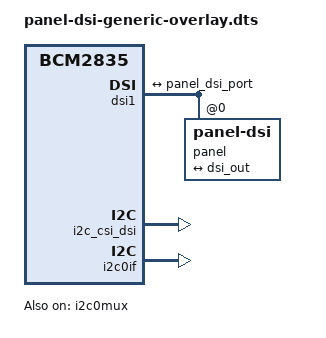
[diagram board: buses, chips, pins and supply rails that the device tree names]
/dts-v1/;
/plugin/;

/ {
	compatible = "brcm,bcm2835";

	dsi_frag: fragment@0 {
		target = <&dsi1>;
		__overlay__{
			status = "okay";
			#address-cells = <1>;
			#size-cells = <0>;
			port {
					dsi_out:endpoint {
							remote-endpoint = <&panel_dsi_port>;
					};
			};
			panel: panel-dsi-generic@0 {
				// See panel-dsi.yml binding for more information
				compatible = "panel-dsi";
				reg = <0>;
				power-supply = <0>;
				backlight = <0>;
				dsi-color-format = "RGB888";
				data-lanes = <1>;
				mode = "";
				width-mm = <0>;
				height-mm = <0>;

				port {
					panel_dsi_port: endpoint {
						remote-endpoint = <&dsi_out>;
					};
				};

				timing: panel-timing {
					clock-frequency = <30000000>;
					hactive = <840>;
					vactive = <480>;
					hback-porch = <44>;
					hfront-porch = <46>;
					hsync-len = <2>;
					vback-porch = <18>;
					vfront-porch = <16>;
					vsync-len = <2>;
				};
			};
		};
	};

	fragment@1 {
		target = <&panel>;
		__dormant__ {
			data-lanes = <1>;
		};
	};

	fragment@2 {
		target = <&panel>;
		__dormant__ {
			data-lanes = <1 2>;
		};
	};

	fragment@3 {
		target = <&panel>;
		__dormant__ {
			data-lanes = <1 2 3>;
		};
	};
	
	fragment@4 {
		target = <&panel>;
		__dormant__ {
			data-lanes = <1 2 3 4>;
		};
	};
	
	fragment@5 {
		target = <&panel>;
		__dormant__ {
			mode = "MODE_VIDEO";
		};
	};

	i2c_frag: fragment@6 {
		target = <&i2c_csi_dsi>;
		__overlay__ {
			#address-cells = <1>;
			#size-cells = <0>;
			status = "okay";

		};
	};

	fragment@7 {
		target = <&i2c0if>;
		__overlay__ {
			status = "okay";
		};
	};

	fragment@8 {
		target = <&i2c0mux>;
		__overlay__ {
			status = "okay";
		};
	};

	__overrides__ {
		dsi0 = <&dsi_frag>, "target:0=",<&dsi0>,
			<&i2c_frag>, "target:0=",<&i2c_csi_dsi0>;

		clock-frequency = <&timing>, "clock-frequency:0";
		hactive = <&timing>, "hactive:0";
		hfp = <&timing>, "hfront-porch:0";
		hsync = <&timing>, "hsync-len:0";
		hbp = <&timing>, "hback-porch:0";
		vactive = <&timing>, "vactive:0";
		vfp = <&timing>, "vfront-porch:0";
		vsync = <&timing>, "vsync-len:0";
		vbp = <&timing>, "vback-porch:0";

		width-mm = <&panel>, "width-mm:0";
		height-mm = <&panel>, "height-mm:0";

		rgb565 = <&panel>, "dsi-color-format=RGB565";
		rgb666p = <&panel>, "dsi-color-format=RGB666_PACKED";
		rgb666 = <&panel>, "dsi-color-format=RGB666";
		rgb888 = <&panel>, "dsi-color-format=RGB888";
		one_lane = <0>,"+1";
		two_lane = <0>,"+2";
		three_lane = <0>,"+3";
		four_lane = <0>,"+4";
		mode_video = <0>,"+5";
	};

};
